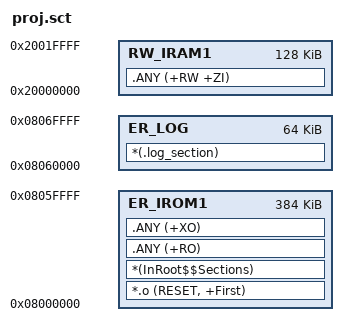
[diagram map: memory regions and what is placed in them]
; *************************************************************
; *** Scatter-Loading Description File generated by uVision ***
; *************************************************************

LR_IROM1 0x08000000 0x00080000  {    ; load region size_region
	;主程序区：使用Sector 0-6（前448KB）
  ER_IROM1 0x08000000 0x00060000  {  ; load address = execution address
   *.o (RESET, +First)
   *(InRoot$$Sections)
   .ANY (+RO)
   .ANY (+XO)
  }
  
  ; 日志存储区：最后16KB
  ; 这个区域不会被.ANY (+RO/+XO)自动分配
  ER_LOG 0x08060000 0x00010000  {    ; 64KB
   *(.log_section)                   ; 只放我们指定的日志段
  }
  
  RW_IRAM1 0x20000000 0x00020000  {  ; RW data
   .ANY (+RW +ZI)
  }
}

